# STM32WL3R register map
File version: 1.0
CPU: CM0+ r0p0, little endian, MPU, no FPU, 4 interrupt priority bits
Registers are 32-bit, read-write, reset 0x0 unless marked. A register's access mark holds for its fields unless they carry their own. Offsets are from the block's base; [hi:lo] are bit positions; {n}, {i} and the like mark numbered series.

## TIMER2 — TIMER2 address block description
Base 0x40002000
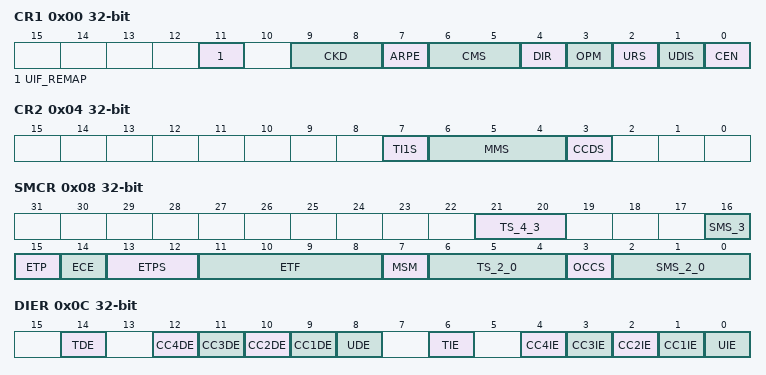
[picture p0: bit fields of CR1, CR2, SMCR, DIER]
0x00 CR1 (reset mask 0xF)
  [11] UIF_REMAP — UIFREMAP: UIF status bit remapping
  [9:8] CKD — CKD[1:0]: Clock division
  [7] ARPE — ARPE: Auto-reload preload enable
  [6:5] CMS — CMS[1:0]: Center-aligned mode selection
  [4] DIR — DIR: Direction
  [3] OPM — OPM: One pulse mode
  [2] URS — URS: Update request source
  [1] UDIS — UDIS: Update disable
  [0] CEN — CEN: Counter enable
0x04 CR2 (reset mask 0xF)
  [7] TI1S — TI1S: TI1 selection
  [6:4] MMS — MMS[2:0]: Master mode selection
  [3] CCDS — CCDS: Capture/compare DMA selection
0x08 SMCR reset not defined
  [21:20] TS_4_3 — Trigger selection.
  [16] SMS_3 — SMS[3]: Slave mode selection - bit 3
  [15] ETP — ETP: External trigger polarity
  [14] ECE — ECE: External clock enable
  [13:12] ETPS — ETPS[1:0]: External trigger prescaler
  [11:8] ETF — ETF[3:0]: External trigger filter
  [7] MSM — MSM: Master/Slave mode
  [6:4] TS_2_0 — TS[4:0]: Trigger selection
  [3] OCCS — OCCS: OCREF clear selection
  [2:0] SMS_2_0 — SMS: Slave mode selection
0x0C DIER (reset mask 0xF)
  [14] TDE — TDE: Trigger DMA request enable
  [n+8] CC{n}DE (n=1..4) — CC{n}DE: Capture/Compare {n} DMA request enable
  [8] UDE — UDE: Update DMA request enable
  [6] TIE — TIE: Trigger interrupt enable
  [n] CC{n}IE (n=1..4) — CC{n}IE: Capture/Compare {n} interrupt enable
  [0] UIE — UIE: Update interrupt enable
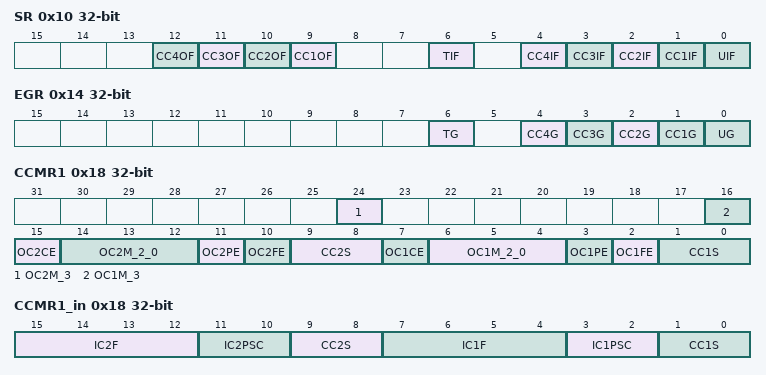
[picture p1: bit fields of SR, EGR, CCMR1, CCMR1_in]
0x10 SR (reset mask 0xF)
  [n+8] CC{n}OF (n=1..4) — CC{n}OF: Capture/Compare {n} overcapture flag
  [6] TIF — TIF: Trigger interrupt flag
  [n] CC{n}IF (n=1..4) — CC{n}IF: Capture/Compare {n} interrupt flag
  [0] UIF — UIF: Update interrupt flag
0x14 EGR (reset mask 0xF)
  [6] TG wo — TG: Trigger generation
  [n] CC{n}G wo (n=1..4) — CC{n}G: Capture/Compare {n} generation
  [0] UG wo — UG: Update generation
0x18 CCMR1 (reset mask 0xF)
  [24] OC2M_3 — OC2M[3]: Output Compare 2 mode (bit 3)
  [16] OC1M_3 — OC1M[3]: Output Compare 1 mode (bit 3)
  [15] OC2CE — OC2CE: Output Compare 2 clear enable
  [14:12] OC2M_2_0 — OC2M[2:0]: Output Compare 2 mode
  [11] OC2PE — OC2PE: Output Compare 2 preload enable
  [10] OC2FE — OC2FE: Output Compare 2 fast enable
  [9:8] CC2S — CC2S[1:0]: Capture/Compare 2 selection
  [7] OC1CE — OC1CE: Output Compare 1 Clear Enable
  [6:4] OC1M_2_0 — OC1M: Output Compare 1 mode
  [3] OC1PE — OC1PE: Output Compare 1 preload enable
  [2] OC1FE — OC1FE: Output Compare 1 fast enable
  [1:0] CC1S — CC1S: Capture/Compare 1 Selection
0x18 CCMR1_in (reset mask 0xF) (alternate view of CCMR1)
  [15:12] IC2F — IC2F: Input capture 2 filter
  [11:10] IC2PSC — IC2PSC[1:0]: Input capture 2 prescaler
  [9:8] CC2S — CC2S: Capture/Compare 2 selection
  [7:4] IC1F — Bits 7:4 IC1F[3:0]: Input capture 1 filter
  [3:2] IC1PSC — IC1PSC: Input capture 1 prescaler
  [1:0] CC1S — CC1S: Capture/Compare 1 Selection
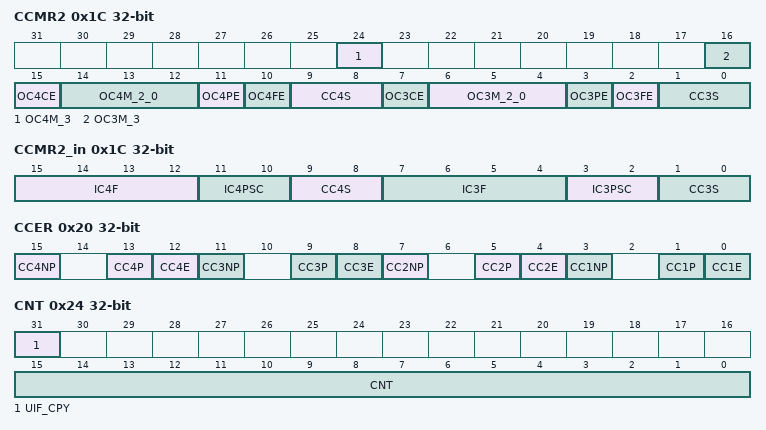
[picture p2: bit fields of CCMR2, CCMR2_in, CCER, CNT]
0x1C CCMR2 (reset mask 0xF)
  [24] OC4M_3 — OC4M[3]: Output Compare 4 mode (bit 3)
  [16] OC3M_3 — OC3M[3]: Output Compare 3 mode (bit 3)
  [15] OC4CE — OC4CE: Output Compare 4 clear enable
  [14:12] OC4M_2_0 — OC4M[2:0]: Output Compare 4 mode
  [11] OC4PE — OC4PE: Output Compare 4 preload enable
  [10] OC4FE — OC4FE: Output Compare 4 fast enable
  [9:8] CC4S — CC4S: Capture/Compare 4 selection
  [7] OC3CE — OC3CE: Output compare 3 clear enable
  [6:4] OC3M_2_0 — OC3M: Output compare 3 mode
  [3] OC3PE — OC3PE: Output compare 3 preload enable
  [2] OC3FE — OC3FE: Output compare 3 fast enable
  [1:0] CC3S — CC3S: Capture/Compare 3 selection
0x1C CCMR2_in (reset mask 0xF) (alternate view of CCMR2)
  [15:12] IC4F — IC4F: Input capture 4 filter
  [11:10] IC4PSC — IC4PSC: Input capture 4 prescaler
  [9:8] CC4S — CC4S: Capture/Compare 4 selection
  [7:4] IC3F — IC3F: Input capture 3 filter
  [3:2] IC3PSC — IC3PSC: Input capture 3 prescaler
  [1:0] CC3S — CC3S: Capture/compare 3 selection
0x20 CCER (reset mask 0xF)
  [15] CC4NP — CC4NP: Capture/Compare 4 Complementary output Polarity.
  [4n-3] CC{n}P (n=1..4) — CC{n}P: Capture/Compare {n} output polarity
  [4n-4] CC{n}E (n=1..4) — CC{n}E: Capture/Compare {n} output enable
  [11] CC3NP — CC3NP: Capture/Compare 3 Complementary output Polarity.
  [7] CC2NP — CC2NP: Capture/Compare 2 Complementary output Polarity.
  [3] CC1NP — CC1NP: Capture/Compare 1 Complementary output Polarity.
    0=OC1N active high; 1=OC1N active low
0x24 CNT (reset mask 0xF)
  [31] UIF_CPY ro — UIFCPY: UIF Copy
  [15:0] CNT — CNT[15:0]: Counter value
0x28 PSC (reset mask 0xF)
  [15:0] PSC — PSC[15:0]: Prescaler value
0x2C ARR reset 0xFFFF
  [15:0] ARR — ARR[15:0]: Prescaler value
0x30 RCR (reset mask 0xF)
  [7:0] REP — REP[7:0]: Repetition counter value
{0x30+4i} CCR{i} (reset mask 0xF) (i=1..4)
  [15:0] CCR{i} — CCR{i}[15:0]: Capture/Compare {i} value
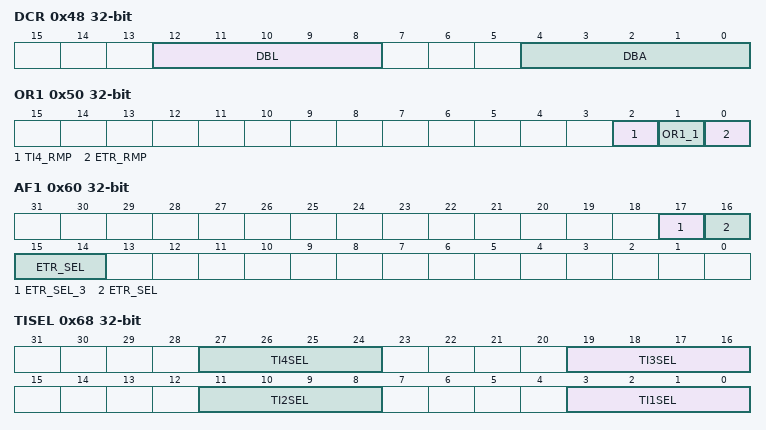
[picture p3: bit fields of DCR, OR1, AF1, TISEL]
0x48 DCR (reset mask 0xF)
  [12:8] DBL — DBL[4:0]: DMA burst length
  [4:0] DBA — DBA[4:0]: DMA base address
0x4C DMAR (reset mask 0xF)
  [15:0] DMAB — DMAB[15:0]: DMA register for burst accesses
0x50 OR1
  [2] TI4_RMP — TI4_RMP: Input capture 4 remap
  [1] OR1_1 — This field is not used in Blue51.
  [0] ETR_RMP — ETR_RMP: ETR remapping capability
0x60 AF1 (reset mask 0xF)
  [17] ETR_SEL_3 — ETRSEL[2:0]: External trigger source selection
  [16:14] ETR_SEL — ETRSEL[2:0]: External trigger source selection
0x68 TISEL (reset mask 0xF)
  [8n-5:8n-8] TI{n}SEL (n=1..4) — TI{n}SEL[3:0]: selects TI{n}[0] to TI{n}[15] input
